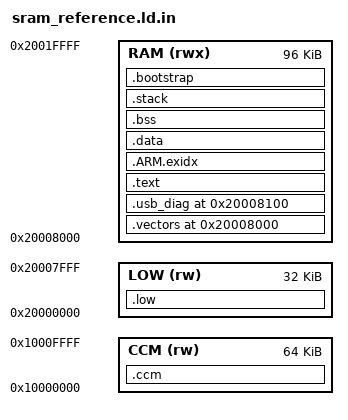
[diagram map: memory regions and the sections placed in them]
ENTRY(Reset_Handler)
MEMORY { RAM (rwx) : ORIGIN = 0x20008000, LENGTH = 96K
         LOW (rw) : ORIGIN = 0x20000000, LENGTH = 32K
         CCM (rw) : ORIGIN = 0x10000000, LENGTH = 64K }
PHDRS { vec PT_LOAD FLAGS(4); code PT_LOAD FLAGS(5); data PT_LOAD FLAGS(6); }
SECTIONS {
 .vectors 0x20008000 : {KEEP(*(.vectors))} > RAM :vec
 .usb_diag 0x20008100 : {KEEP(*(.usb_diag))} > RAM :vec
 .text : {KEEP(*(.text.entry)) *(.text*) *(.rodata*)} > RAM :code
 .ARM.exidx : {*(.ARM.exidx*)} > RAM :code
 .data : {*(.data*) . = ALIGN(4); __load_end = .;} > RAM :data
 .bss (NOLOAD) : {. = ALIGN(32); __bss_begin = .; *(.bss*) *(COMMON) . = ALIGN(8); __bss_end = .;} > RAM :data
 .stack (NOLOAD) : {. = ALIGN(8); __stack_guard_bottom = .; . += 64; __stack_bottom = .; . += STACK_BYTES; __stack_top = .;} > RAM :data
 .bootstrap (NOLOAD) : {. += 128; __boot_stack_top = .;} > RAM :data
 .low (NOLOAD) : {. = ALIGN(32); __low_begin = .; *(.low*) . = ALIGN(8); __low_end = .;} > LOW :NONE
 .ccm (NOLOAD) : {. = ALIGN(32); __ccm_begin = .; *(.ccm*) . = ALIGN(8); __ccm_end = .;} > CCM :NONE
 /DISCARD/ : {*(.comment) *(.note*)}
}
ASSERT(__boot_stack_top < 0x20020000,"upper SRAM overrun")
ASSERT(__low_end <= 0x20008000,"lower SRAM overrun")
ASSERT(__ccm_end <= 0x10010000,"CCM overrun")
__image_bytes = ABSOLUTE(__load_end - 0x20008000);
__reserved_ram = ABSOLUTE(__boot_stack_top - 0x20008000) + ABSOLUTE(__ccm_end - 0x10000000) + ABSOLUTE(__low_end - 0x20000000);

